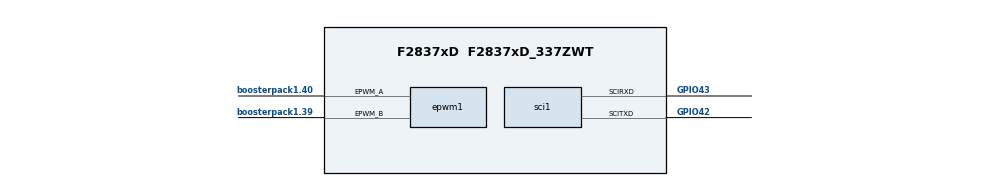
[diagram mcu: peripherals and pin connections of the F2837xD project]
/**
 * @cliArgs --board "/boards/LAUNCHXL_F28379D" --device "F2837xD" --part "F2837xD_337ZWT" --package "F2837xD_337ZWT" --context "CPU1" --product "C2000WARE@26.00.00.00"
 * @versions {"tool":"1.27.1+4634"}
 */

/**
 * Import the modules used in this configuration.
 */
const asysctl          = scripting.addModule("/driverlib/asysctl.js");
const cla              = scripting.addModule("/driverlib/cla.js", {}, false);
const cla1             = cla.addInstance();
const epwm             = scripting.addModule("/driverlib/epwm.js", {}, false);
const epwm1            = epwm.addInstance();
const inputxbar_input  = scripting.addModule("/driverlib/inputxbar_input.js", {}, false);
const inputxbar_input1 = inputxbar_input.addInstance();
const inputxbar_input2 = inputxbar_input.addInstance();
const inputxbar_input3 = inputxbar_input.addInstance();
const inputxbar_input4 = inputxbar_input.addInstance();
const memcfg           = scripting.addModule("/driverlib/memcfg.js");
const sci              = scripting.addModule("/driverlib/sci.js", {}, false);
const sci1             = sci.addInstance();

/**
 * Write custom configuration values to the imported modules.
 */
cla1.$name             = "myCLA0";
cla1.enable_CLA_TASK_8 = false;
cla1.enable_CLA_TASK_7 = false;
cla1.enable_CLA_TASK_6 = false;
cla1.enable_CLA_TASK_5 = false;
cla1.enable_CLA_TASK_4 = false;
cla1.enable_CLA_TASK_3 = false;
cla1.enable_CLA_TASK_2 = false;
cla1.cpuint_CLA_TASK_8 = false;
cla1.cpuint_CLA_TASK_6 = false;
cla1.cpuint_CLA_TASK_5 = false;
cla1.cpuint_CLA_TASK_7 = false;
cla1.cpuint_CLA_TASK_4 = false;
cla1.cpuint_CLA_TASK_3 = false;
cla1.cpuint_CLA_TASK_2 = false;

epwm1.$name                                                      = "myEPWM0";
epwm1.epwmTimebase_hsClockDiv                                    = "EPWM_HSCLOCK_DIVIDER_1";
epwm1.epwmTimebase_period                                        = 5000;
epwm1.epwmTimebase_counterMode                                   = "EPWM_COUNTER_MODE_UP_DOWN";
epwm1.epwmCounterCompare_cmpA                                    = 3750;
epwm1.epwmActionQualifier_EPWM_AQ_OUTPUT_A_shadowMode            = true;
epwm1.epwmActionQualifier_EPWM_AQ_OUTPUT_A_ON_TIMEBASE_UP_CMPA   = "EPWM_AQ_OUTPUT_HIGH";
epwm1.epwmActionQualifier_EPWM_AQ_OUTPUT_A_ON_TIMEBASE_DOWN_CMPA = "EPWM_AQ_OUTPUT_LOW";
epwm1.epwm.$assign                                               = "EPWM1";
epwm1.epwm.epwm_aPin.$assign                                     = "boosterpack1.40";
epwm1.epwm.epwm_bPin.$assign                                     = "boosterpack1.39";

inputxbar_input1.$name          = "myINPUTXBARINPUT0";
inputxbar_input1.inputxbarInput = "XBAR_INPUT4";
inputxbar_input1.inputxbarGpio  = "GPIO1";

inputxbar_input2.$name          = "myINPUTXBARINPUT1";
inputxbar_input2.inputxbarInput = "XBAR_INPUT5";
inputxbar_input2.inputxbarGpio  = "GPIO1";

inputxbar_input3.$name          = "myINPUTXBARINPUT2";
inputxbar_input3.inputxbarInput = "XBAR_INPUT6";
inputxbar_input3.inputxbarGpio  = "GPIO3";

inputxbar_input4.$name          = "myINPUTXBARINPUT3";
inputxbar_input4.inputxbarInput = "XBAR_INPUT13";
inputxbar_input4.inputxbarGpio  = "GPIO4";

memcfg.init_MEMCFG_SECT_MSGCLA1TOCPU = true;
memcfg.init_MEMCFG_SECT_MSGCPUTOCLA1 = true;
memcfg.config_MEMCFG_SECT_LS1        = "CLA_data";
memcfg.config_MEMCFG_SECT_LS4        = "CLA_prog";
memcfg.config_MEMCFG_SECT_LS5        = "CLA_prog";

sci1.$name                      = "SCI0";
sci1.selectRegisteredInterrupts = ["registerRxInt"];
sci1.enabledFIFOInterrupts      = ["SCI_INT_RXFF"];
sci1.rxFifo                     = "SCI_FIFO_RX1";
sci1.useInterrupts              = false;
sci1.sci.scirxdPin.$assign      = "GPIO43";
sci1.sci.scitxdPin.$assign      = "GPIO42";
sci1.rxQual.$name               = "myGPIOQUAL0";
sci1.txQual.$name               = "myGPIOQUAL1";

/**
 * Pinmux solution for unlocked pins/peripherals. This ensures that minor changes to the automatic solver in a future
 * version of the tool will not impact the pinmux you originally saw.  These lines can be completely deleted in order to
 * re-solve from scratch.
 */
sci1.sci.$suggestSolution = "SCIA";
